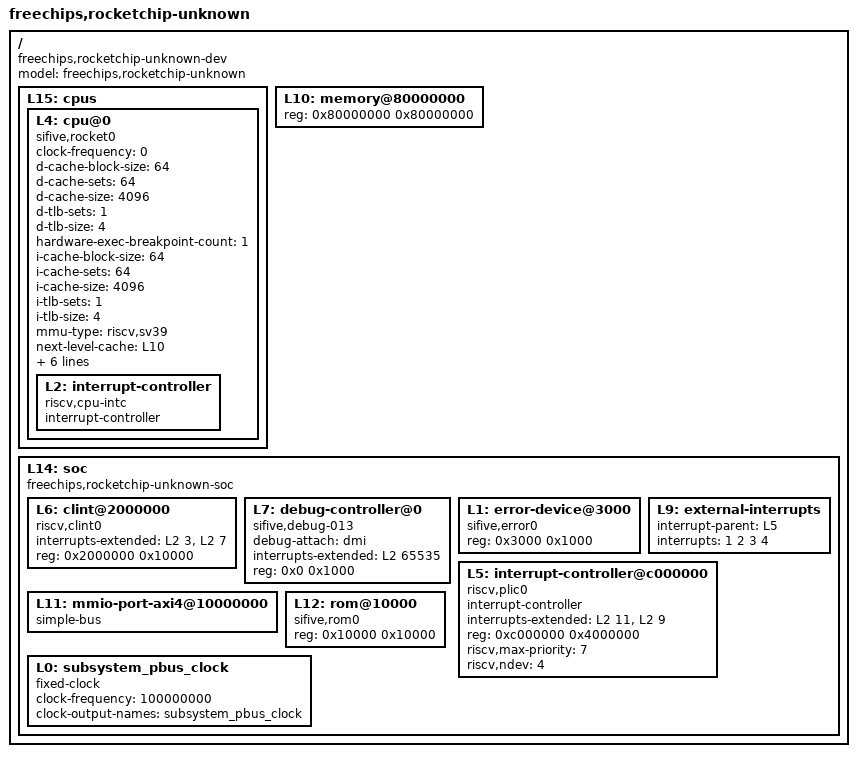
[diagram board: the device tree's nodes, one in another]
/dts-v1/;

/ {
	#address-cells = <1>;
	#size-cells = <1>;
	compatible = "freechips,rocketchip-unknown-dev";
	model = "freechips,rocketchip-unknown";
	L15: cpus {
		#address-cells = <1>;
		#size-cells = <0>;
		L4: cpu@0 {
			clock-frequency = <0>;
			compatible = "sifive,rocket0", "riscv";
			d-cache-block-size = <64>;
			d-cache-sets = <64>;
			d-cache-size = <4096>;
			d-tlb-sets = <1>;
			d-tlb-size = <4>;
			device_type = "cpu";
			hardware-exec-breakpoint-count = <1>;
			i-cache-block-size = <64>;
			i-cache-sets = <64>;
			i-cache-size = <4096>;
			i-tlb-sets = <1>;
			i-tlb-size = <4>;
			mmu-type = "riscv,sv39";
			next-level-cache = <&L10>;
			reg = <0x0>;
			riscv,isa = "rv64imac";
			riscv,pmpgranularity = <4>;
			riscv,pmpregions = <8>;
			status = "okay";
			timebase-frequency = <1000000>;
			tlb-split;
			L2: interrupt-controller {
				#interrupt-cells = <1>;
				compatible = "riscv,cpu-intc";
				interrupt-controller;
			};
		};
	};
	L10: memory@80000000 {
		device_type = "memory";
		reg = <0x80000000 0x80000000>;
	};
	L14: soc {
		#address-cells = <1>;
		#size-cells = <1>;
		compatible = "freechips,rocketchip-unknown-soc", "simple-bus";
		ranges;
		L6: clint@2000000 {
			compatible = "riscv,clint0";
			interrupts-extended = <&L2 3 &L2 7>;
			reg = <0x2000000 0x10000>;
			reg-names = "control";
		};
		L7: debug-controller@0 {
			compatible = "sifive,debug-013", "riscv,debug-013";
			debug-attach = "dmi";
			interrupts-extended = <&L2 65535>;
			reg = <0x0 0x1000>;
			reg-names = "control";
		};
		L1: error-device@3000 {
			compatible = "sifive,error0";
			reg = <0x3000 0x1000>;
		};
		L9: external-interrupts {
			interrupt-parent = <&L5>;
			interrupts = <1 2 3 4>;
		};
		L5: interrupt-controller@c000000 {
			#interrupt-cells = <1>;
			compatible = "riscv,plic0";
			interrupt-controller;
			interrupts-extended = <&L2 11 &L2 9>;
			reg = <0xc000000 0x4000000>;
			reg-names = "control";
			riscv,max-priority = <7>;
			riscv,ndev = <4>;
		};
		L11: mmio-port-axi4@10000000 {
			#address-cells = <1>;
			#size-cells = <1>;
			compatible = "simple-bus";
			ranges = <0x10000000 0x10000000 0x70000000>;
		};
		L12: rom@10000 {
			compatible = "sifive,rom0";
			reg = <0x10000 0x10000>;
			reg-names = "mem";
		};
		L0: subsystem_pbus_clock {
			#clock-cells = <0>;
			clock-frequency = <100000000>;
			clock-output-names = "subsystem_pbus_clock";
			compatible = "fixed-clock";
		};
	};
};
